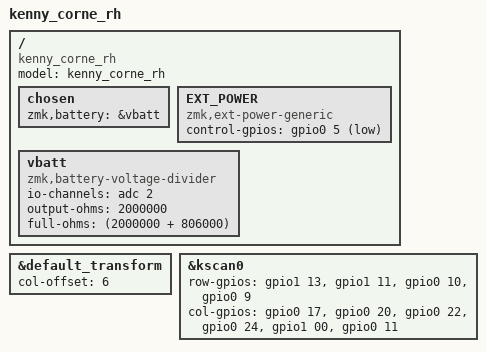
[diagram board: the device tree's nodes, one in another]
/dts-v1/;
#include <nordic/nrf52840_qiaa.dtsi>

#include <dt-bindings/led/led.h>
#include <dt-bindings/zmk/matrix_transform.h>

#include "kenny_corne.dtsi"
#include "kenny_corne_rh-pinctrl.dtsi"

/ {
    model = "kenny_corne_rh";
    compatible = "kenny_corne_rh";

    chosen {
        zmk,battery = &vbatt;
    };

    // Node name must match original "EXT_POWER" label to preserve user settings.
    EXT_POWER {
        compatible = "zmk,ext-power-generic";
        control-gpios = <&gpio0 5 GPIO_ACTIVE_LOW>;
    };

    vbatt: vbatt {
        compatible = "zmk,battery-voltage-divider";
        io-channels = <&adc 2>;
        output-ohms = <2000000>;
        full-ohms = <(2000000 + 806000)>;
    };
};


&default_transform {
    col-offset = <6>;
};

&kscan0 {
    row-gpios
        = <&gpio1 13 (GPIO_ACTIVE_HIGH | GPIO_PULL_DOWN)>
        , <&gpio1 11 (GPIO_ACTIVE_HIGH | GPIO_PULL_DOWN)>
        , <&gpio0 10 (GPIO_ACTIVE_HIGH | GPIO_PULL_DOWN)>
        , <&gpio0  9 (GPIO_ACTIVE_HIGH | GPIO_PULL_DOWN)>
        ;
    col-gpios
        = <&gpio0 17 GPIO_ACTIVE_HIGH>
        , <&gpio0 20 GPIO_ACTIVE_HIGH>
        , <&gpio0 22 GPIO_ACTIVE_HIGH>
        , <&gpio0 24 GPIO_ACTIVE_HIGH>
        , <&gpio1 00 GPIO_ACTIVE_HIGH>
        , <&gpio0 11 GPIO_ACTIVE_HIGH>
        ;
};
